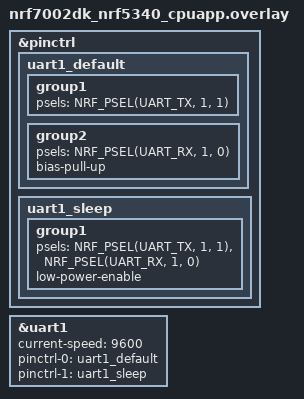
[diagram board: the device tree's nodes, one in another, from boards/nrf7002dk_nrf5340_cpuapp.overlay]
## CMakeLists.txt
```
#
# Copyright (c) 2022 Nordic Semiconductor ASA
#
# SPDX-License-Identifier: LicenseRef-Nordic-5-Clause
#

cmake_minimum_required(VERSION 3.20.0)

find_package(Zephyr REQUIRED HINTS $ENV{ZEPHYR_BASE})
project(GNSSProjekt3)

target_include_directories(app PUBLIC ${ZEPHYR_BASE}/subsys/net/ip)

target_sources(app
    PRIVATE
    src/main.c
    src/gps.c
    src/net_comm.c
    src/led_blink.c
)
```

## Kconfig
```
#
# Copyright (c) 2022 Nordic Semiconductor
#
# SPDX-License-Identifier: LicenseRef-Nordic-5-Clause
#

source "Kconfig.zephyr"

menu "Nordic Sta sample"

config CONNECTION_IDLE_TIMEOUT
	int "Time to be waited for a station to connect"
	default 30

config NRF70_QSPI_ENCRYPTION_KEY
	string "16 bytes QSPI encryption key, only for testing purposes"
	depends on BOARD_NRF7002DK_NRF5340_CPUAPP
	help
	  Specify the QSPI encryption key

config STA_CONN_TIMEOUT_SEC
	int "Overall Connection timeout i.e., time to be waited for a station to connect and get an IP address"
	# Zephyr DHCP retry is 1 minute, so set the default to 70 seconds
	default 70
	# 512 has no special meaning, just a reasonable upper limit
	range 0 512
	help
	  Specify the connection timeout, in seconds. This is the overall timeout i.e., time to be waited for
	  a station to connect and get an IP address. DHCP retries should be taken into account when setting
	  this value. If the timeout is set to 0, the connection will not timeout.

config STA_SAMPLE_START_WIFI_THREAD_STACK_SIZE
	int "Stack size for Wi-Fi start thread"
	default 4096
	help
	  Set the stack size for the Wi-Fi start thread.
	  
endmenu
```

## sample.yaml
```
sample:
  description: Wi-Fi station sample
    application
  name: Wi-Fi station
tests:
  sample.nrf7002.sta:
    sysbuild: true
    build_only: true
    integration_platforms:
      - nrf7002dk/nrf5340/cpuapp
    platform_allow: nrf7002dk/nrf5340/cpuapp
    tags: ci_build sysbuild ci_samples_wifi
  sample.nrf7002.sta.no_wifi_ready:
    sysbuild: true
    build_only: true
    extra_args: CONFIG_WIFI_READY_LIB=n
    integration_platforms:
      - nrf7002dk/nrf5340/cpuapp
    platform_allow: nrf7002dk/nrf5340/cpuapp
    tags: ci_build sysbuild ci_samples_wifi
  sample.nrf7001.sta:
    sysbuild: true
    build_only: true
    integration_platforms:
      - nrf7002dk/nrf5340/cpuapp/nrf7001
    platform_allow: nrf7002dk/nrf5340/cpuapp/nrf7001
    tags: ci_build sysbuild ci_samples_wifi
    skip: true
  sample.nrf7002_eks.sta:
    sysbuild: true
    build_only: true
    extra_args: SHIELD=nrf7002ek
    integration_platforms:
      - nrf5340dk/nrf5340/cpuapp
      - nrf52840dk/nrf52840
    platform_allow: nrf5340dk/nrf5340/cpuapp nrf52840dk/nrf52840
    extra_configs:
      - CONFIG_NET_TX_STACK_SIZE=3700
      - CONFIG_NET_RX_STACK_SIZE=3700
    tags: ci_build sysbuild ci_samples_wifi
  sample.nrf7001_eks.sta:
    sysbuild: true
    build_only: true
    extra_args: SHIELD=nrf7002ek_nrf7001
    integration_platforms:
      - nrf5340dk/nrf5340/cpuapp
      - nrf52840dk/nrf52840
    platform_allow: nrf5340dk/nrf5340/cpuapp nrf52840dk/nrf52840
    extra_configs:
      - CONFIG_NET_TX_STACK_SIZE=3700
      - CONFIG_NET_RX_STACK_SIZE=3700
    tags: ci_build sysbuild ci_samples_wifi
  sample.nrf7002_eb.thingy53.sta:
    sysbuild: true
    build_only: true
    extra_args: sta_SHIELD=nrf7002eb
    integration_platforms:
      - thingy53/nrf5340/cpuapp
    platform_allow: thingy53/nrf5340/cpuapp
    tags: ci_build sysbuild ci_samples_wifi
  sample.nrf7002eb_interposer_p1.nrf7002eb.sta:
    sysbuild: true
    build_only: true
    extra_args:
      - sta_SHIELD=nrf7002eb_interposer_p1 nrf7002eb
      - sta_SNIPPET=nrf70-wifi
    integration_platforms:
      - nrf54h20dk/nrf54h20/cpuapp
      - nrf54l15dk/nrf54l15/cpuapp
    platform_allow:
      - nrf54h20dk/nrf54h20/cpuapp
      - nrf54l15dk/nrf54l15/cpuapp
    tags: ci_build sysbuild ci_samples_wifi
```

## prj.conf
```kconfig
CONFIG_WIFI=y
CONFIG_WIFI_NRF70=y

#WPA supplicant
CONFIG_WIFI_NM_WPA_SUPPLICANT=y
CONFIG_WIFI_READY_LIB=y
CONFIG_NRF_WIFI_RPU_RECOVERY=y

CONFIG_WIFI_MGMT_EXT=y
CONFIG_WIFI_CREDENTIALS=y
CONFIG_WIFI_CREDENTIALS_STATIC=y
CONFIG_WIFI_CREDENTIALS_STATIC_SSID=""
CONFIG_WIFI_CREDENTIALS_STATIC_PASSWORD=""

#Networking
CONFIG_NETWORKING=y
CONFIG_NET_SOCKETS=y
CONFIG_NET_LOG=y
CONFIG_NET_IPV4=y
CONFIG_NET_UDP=y
CONFIG_NET_TCP=y
CONFIG_NET_DHCPV4=y

CONFIG_NET_PKT_RX_COUNT=8
CONFIG_NET_PKT_TX_COUNT=8


CONFIG_NET_BUF_RX_COUNT=128
CONFIG_NET_BUF_TX_COUNT=128
CONFIG_NRF70_RX_NUM_BUFS=16
CONFIG_HEAP_MEM_POOL_SIZE=120000
CONFIG_HEAP_MEM_POOL_IGNORE_MIN=y
CONFIG_NET_TC_TX_COUNT=1

CONFIG_NET_IF_UNICAST_IPV4_ADDR_COUNT=1
CONFIG_NET_MAX_CONTEXTS=5
CONFIG_NET_CONTEXT_SYNC_RECV=y

CONFIG_INIT_STACKS=y

CONFIG_NET_L2_ETHERNET=y

CONFIG_NET_CONFIG_SETTINGS=y 
CONFIG_NET_CONFIG_INIT_TIMEOUT=0

CONFIG_NET_SOCKETS_POLL_MAX=10

# Memories
CONFIG_MAIN_STACK_SIZE=5200
CONFIG_NET_TX_STACK_SIZE=4096
CONFIG_NET_RX_STACK_SIZE=4096
CONFIG_STA_SAMPLE_START_WIFI_THREAD_STACK_SIZE=5200

#Debugging
CONFIG_STACK_SENTINEL=y
CONFIG_DEBUG_COREDUMP=y
CONFIG_DEBUG_COREDUMP_BACKEND_LOGGING=y
CONFIG_DEBUG_COREDUMP_MEMORY_DUMP_MIN=y
CONFIG_SHELL_CMDS_RESIZE=n



CONFIG_ENTROPY_GENERATOR=y

CONFIG_NET_CONFIG_MY_IPV4_ADDR="192.168.1.99"
CONFIG_NET_CONFIG_MY_IPV4_NETMASK="255.255.255.0"
CONFIG_NET_CONFIG_MY_IPV4_GW="192.168.1.1"

CONFIG_NET_MGMT_EVENT_QUEUE_TIMEOUT=5000

#Logging
CONFIG_LOG=y
CONFIG_LOG_BUFFER_SIZE=2048
CONFIG_POSIX_CLOCK=y

#GTPA013 UART COMMUNICATION
CONFIG_SERIAL=y
CONFIG_UART_INTERRUPT_DRIVEN=n
CONFIG_UART_ASYNC_API=y


CONFIG_PRINTK=y

CONFIG_UART_ASYNC_API=y
CONFIG_UART_INTERRUPT_DRIVEN=n

CONFIG_HEAP_MEM_POOL_SIZE=120000


#Traccar HTTP section
CONFIG_HTTP_CLIENT=y
#needed to activate float
CONFIG_CBPRINTF_FP_SUPPORT=y

#needed for leds
CONFIG_GPIO=y
```

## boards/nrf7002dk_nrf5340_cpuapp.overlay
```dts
// Allow uart1 to be used as a normal UART instead of forwarding to network core for serial logging
/delete-node/ &gpio_fwd;



&pinctrl {

    uart1_default: uart1_default {
		group1 {
			psels = <NRF_PSEL(UART_TX, 1, 1)>;
		};
		group2 {
			psels = <NRF_PSEL(UART_RX, 1, 0)>;
			bias-pull-up;
		};
	};

	uart1_sleep: uart1_sleep {
		group1 {
			psels = <NRF_PSEL(UART_TX, 1, 1)>,
				<NRF_PSEL(UART_RX, 1, 0)>;
			low-power-enable;
		};
	};

};





&uart1 {
	status = "okay";
	current-speed = <9600>;
	pinctrl-0 = <&uart1_default>;
	pinctrl-1 = <&uart1_sleep>;
	pinctrl-names = "default", "sleep";
	
};
```

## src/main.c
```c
#include <stdio.h> //standard c lib
#include <stdlib.h> //standard c lib
#include <zephyr/kernel.h>
#include <zephyr/drivers/uart.h> //uart functions and macros

#include <zephyr/sys/util.h> //utility macros(SYS_FOREVER_US)


#include <zephyr/net/net_if.h> //network interfaces 
#include <zephyr/net/net_mgmt.h> //api for controlling net events
#include <zephyr/net/net_event.h> //defines net events
#include <zephyr/net/wifi_mgmt.h> //wifi management scan, connect
 
#include <net/wifi_mgmt_ext.h> //needed for wifi credentials //rxtended API for working with WIFI credentials
#include <net/wifi_ready.h> // macros for wifi interface readyness checking

//SOCKET headers
#include <zephyr/net/socket.h>
#include <zephyr/net/http/client.h>

//led file header
#include "led_blink.h"
#include "gps.h"
#include "net_comm.h"

//logging system setup
LOG_MODULE_REGISTER(main, LOG_LEVEL_INF); //main - module name, LoG_LEVEL_INF - info and above 


int main(void)
{

    printk("main started\n");
    printk("beginning\n");

    if(init_led() != 0){
        return 0;
    }
    blink_led(1, 2000);
    
    struct net_if *iface = net_if_get_default(); //get primary network interface
    if (iface == NULL) {
        LOG_ERR("Wi-Fi interface not found!");
        return 0;
    }

    if(wifi_init(iface) != 0) return 0;

        
    connect_to_wifi_with_backup(iface);
    

	k_sleep(K_MSEC(5000)); // DELAY JER SE INACE PRECOMPLETE I WIFI SETUP COMPLETE ISPISU  NAKON UART TEXTOVA ZBOG NEKOG RAZLOGA
    
    printk("Starting GNSS listener...\n");
	//check if uart device is ready
    if (!device_is_ready(uart)) {
        printk("UART device not ready!\n");
        return 0;
    }
    
    k_sleep(K_MSEC(2000)); // Give GPS time to boot
    configure_gtpa013("$PMTK314,0,1,0,1,0,0,0,0,0,0,0,0,0,0,0,0,0,0,0*28\r\n"); // set only RMC nmea sentence and GGA
    k_sleep(K_MSEC(2));

    //configure_gtpa013("$PMTK220,1000*1F\r\n");// se output interval
    //k_sleep(K_MSEC(10000));

    if(uart_init() != 0) return 0;

    printk("UART RX interrupt listener started\n");

    k_sleep(K_MSEC(5000));
        
    while (1) {
        k_sem_take(&gps_data_sem, K_FOREVER);

        // parse + send latest
        if (nmea_parser(latest_nmea_sentence)) {
            send_to_traccar(lat_dec, lon_dec, user_speed, altitude);
        }

        //if connected is set to false(in case a dicsonnect happened), attempt to reconnect
        if(!connected){
            printk("Attemping to recconnect wifi.");
            connect_to_wifi_with_backup(iface);
        }
        


        k_msleep(1);
    }
        
        
    
}
```

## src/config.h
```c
#ifndef CONFIG_H
#define CONFIG_H

#define SERVER_IP   ""
#define SERVER_PORT 5055
#define DEVICE_ID   ""

#endif 
```

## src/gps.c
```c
#include "gps.h"

#include <stdio.h> 
#include <stdlib.h> 
#include <zephyr/kernel.h>
#include <zephyr/drivers/uart.h> //uart functions and macros
#include <zephyr/sys/util.h> //utility macros(SYS_FOREVER_US)

#define UART_BUF_COUNT 2

#define UART_BUF_SIZE 83   // 82 max length of one nmea sentence

static uint8_t *uart_buffers[UART_BUF_COUNT];
static int uart_buf_idx = 0;
#define UART_DEVICE_NODE DT_NODELABEL(uart1)   //defines macro for UART device node, specifically uart1
const struct device *uart = DEVICE_DT_GET(UART_DEVICE_NODE); //fetch UART device using macro, stores in pointer uart used to comunicate with UART hardware

#define GTPA_DATA_BUFFER_SIZE 1024
static uint8_t gtpa_data_buffer[GTPA_DATA_BUFFER_SIZE];
static size_t gtpa_data_buffer_pos = 0;
char latest_nmea_sentence[128];
K_SEM_DEFINE(gps_data_sem, 0, 1);  //binary semaphore

//amount of commas in a NMEA sentence 
#define NMEA_COMMA_AMOUNT 16

//global data containers for latitude and longitude values
double lat_dec = 0;
double lon_dec = 0;
double user_speed = 0;
double altitude = 0;


static bool validate_checksum(const char *nmea){
    //fint the * marking the beggining of checksum portion
    const char *checksum_str = strchr(nmea, '*');
    if(!checksum_str){
        printk("Invalid checksum\n");
        return false;
    }
    //put the two characters after * representing checksum and a terminator into a buffer
    char checksum_buf[3] = {checksum_str[1], checksum_str[2], '\0'};
    
    //convert checksum characters into base 16
    uint8_t converted_checksum = (uint8_t)strtol(checksum_buf, NULL, 16);

    //calculate checksum - XOR of all characters between $ and *
    uint8_t calculated_checksum = 0;
    for(const char *p = nmea + 1; p < checksum_str; ++p){
        calculated_checksum ^= (uint8_t)(*p);
    }
    printk("Calculated checksum: %02X\n", calculated_checksum);

    //compare checksums, if they match sentence is not corrupted
    if(calculated_checksum != converted_checksum){
        printk("Checksum mismatch: expected %02X, got %02X\n", converted_checksum, calculated_checksum);
        return false;
    }
    return true;
}

float nmea_to_decimal(const char *coord, const char *dir, bool is_latitude){
    float deg = 0;
    float min = 0;
    
    //latitude ddmm.mmmm longitude dddmm.mmmm
    //spliting d and m sections into deg and min floats
    if(is_latitude){
        //2 digits for deg
        char deg_str[3] = {0};
        strncpy(deg_str, coord, 2);
        deg = atof(deg_str);
        min = atof(coord + 2);
    }else{
        //3 digits for deg
        char deg_str[4] = {0};
        strncpy(deg_str, coord, 3);
        deg = atof(deg_str);
        min = atof(coord + 3);
    }
    //formula for converting into decimal
    float decimal = deg + (min / 60);
    // fot lat N is positive, S is negative
    // for lon E is positive, S is negative
    if(dir[0] == 'S' || dir[0] == 'W'){
        decimal = -decimal;
    }

    return decimal;
}

//function to parse nmea sentences
bool nmea_parser(const char *nmea){
    //if sum doesnt match checksum value sentence is corrupted
    if(!validate_checksum(nmea)){
        printk("Invalid checksum. Skipping\n");
        return false;
    }

    char par_buf[128];
    //copy data into modifiable buffer
    strncpy(par_buf, nmea, sizeof(par_buf) - 1);
    par_buf[sizeof(par_buf) - 1] = '\0';

    //separate data by commas
    char *nmea_sections[16];
    int i = 0; // also the amount of commas
    //strtok - function do split string by certain character(in this case ,)
    char *nmea_section = strtok(par_buf, ",");
    while(nmea_section != NULL && i < 16){
        nmea_sections[i++] = nmea_section;
        nmea_section = strtok(NULL, ",");
    }

    if(strncmp(nmea, "$GPRMC", 6) == 0){
    
        const char *utc_time = nmea_sections[1];
        const char *status = nmea_sections[2];
        const char *latitude_raw = nmea_sections[3];
        const char *latitude_dir = nmea_sections[4];
        const char *longitude_raw = nmea_sections[5];
        const char *longitude_dir = nmea_sections[6];
        const char *speed = nmea_sections[7];
        const char *course = nmea_sections[8];
        const char *date = nmea_sections[9];

        if(status[0] != 'A'){
            printk("  GPRMC status not valid: %s\n", status[0] == 'A' ? "Active" : "Void");
            return false;
        }
        // converting lat and lon from ddmm.mmmm to proper decimals
        lat_dec = nmea_to_decimal(latitude_raw, latitude_dir, true);
        lon_dec = nmea_to_decimal(longitude_raw, longitude_dir, false);
        user_speed = atof(speed);
        // Print parsed data
        printk("GPRMC Parsed:\n");
        printk("  UTC Time: %s\n", utc_time);
        printk("  Status: %s\n", status[0] == 'A' ? "Active" : "Void");
        printk("  Latitude: %0.6f\n", lat_dec);
        printk("  Longitude: %0.6f\n", lon_dec);
        printk("  Speed (knots): %s\n", speed);
        printk("  Course: %s\n", course);
        printk("  Date: %s\n", date);
        return true;

    }else if(strncmp(nmea, "$GPGGA", 6) == 0){
        //const char *utc_time = nmea_sections[1];
        const char *latitude_raw = nmea_sections[2];
        const char *latitude_dir = nmea_sections[3];
        const char *longitude_raw = nmea_sections[4];
        const char *longitude_dir = nmea_sections[5];
        const char *fix_quality = nmea_sections[6];
        const char *altitude_raw = nmea_sections[9];

        if(fix_quality[0] != '1' && fix_quality[0] != '2'){
            printk("No GPS fix\n");
            return false;
        }

        lat_dec = nmea_to_decimal(latitude_raw, latitude_dir, true);
        lon_dec = nmea_to_decimal(longitude_raw, longitude_dir, false);
        altitude = atof(altitude_raw); // turn alt into float
        
        printk("GPGGA Parsed:\n");
        printk("  Latitude: %0.6f\n", lat_dec);
        printk("  Longitude: %0.6f\n", lon_dec);
        printk("  Altitude: %0.3f m\n", altitude);
        printk("  Fix Quality: %s\n", fix_quality);
        return true;
    }
        
    return false;
    
}




static void uart_cb(const struct device *dev, struct uart_event *evt, void *user_data)
{
    int err;

	//switch picking what to do based on the event type
    switch (evt->type) {
		//when data is ready to be read
    case UART_RX_RDY:

        //better saving of data which checks for end of sentence and resets buffer position on end
        for(size_t i = 0; i < evt->data.rx.len; i++){
            if(gtpa_data_buffer_pos < GTPA_DATA_BUFFER_SIZE - 1){
                gtpa_data_buffer[gtpa_data_buffer_pos++] = evt->data.rx.buf[evt->data.rx.offset + i];

                if(evt->data.rx.buf[evt->data.rx.offset + i] == '\n'){
                    //end of sentence detected, terminate it and print out data and reset buffer
                    gtpa_data_buffer[gtpa_data_buffer_pos] = '\0';
                    
                    
                   
                    memcpy(latest_nmea_sentence, gtpa_data_buffer, gtpa_data_buffer_pos); 
                     
                    printk("[%u]Full NMEA sentence: %s", k_uptime_get_32(), gtpa_data_buffer);

                    //nmea_parser((const char *)gtpa_data_buffer);
                    k_sem_give(&gps_data_sem);

                    gtpa_data_buffer_pos = 0;
                }
            }else{
                printk("App buffer overflow\n");
                gtpa_data_buffer_pos = 0;
            }
        }
        break;
		//when uart driver requests a buffer for recieving data
    case UART_RX_BUF_REQUEST:
        //switch from currently active to the other buffer
        uart_buf_idx = (uart_buf_idx + 1) % UART_BUF_COUNT;
        uint8_t *next_buf = uart_buffers[uart_buf_idx];

        err = uart_rx_buf_rsp(uart, next_buf, UART_BUF_SIZE);
        if (err) {
            printk("uart_rx_buf_rsp error: %d\n", err);
        }
        break;
     
    case UART_RX_DISABLED:
        printk("UART RX Disabled, re-enabling...\n");
        
        err = uart_rx_enable(uart, uart_buffers[0], UART_BUF_SIZE, SYS_FOREVER_US);
        if (err) {
            printk("uart_rx_enable error: %d\n", err);
        }

        break;
    default:
        break;
    }
}

//function for sending commands to gps module
void configure_gtpa013(const char* command){

    size_t len = strlen(command);
    int ret = uart_tx(uart, command, len, SYS_FOREVER_US);
    k_sleep(K_MSEC(1000));
    if (ret) {
        printk("Failed to send GPS command (err %d)\n", ret);
    } else {
        printk("Sent GPS command: %s\n", command);
    }
}

int uart_init(void)
{
    int err;

    int ret = uart_callback_set(uart, uart_cb, NULL);
    if (ret) {
        printk("Failed to set UART callback: %d\n", ret);
        return -1;
    }

    //allocate both buffers
    for (int i = 0; i < UART_BUF_COUNT; i++) {
        uart_buffers[i] = k_malloc(UART_BUF_SIZE);
        if (!uart_buffers[i]) {
            printk("Failed to allocate UART buffer %d\n", i);
            return -1;
        }
    }
    k_msleep(1000);
    //enable uart rx with the first buffer
    err = uart_rx_enable(uart, uart_buffers[0], UART_BUF_SIZE, SYS_FOREVER_US);
    if (err) {
        printk("uart_rx_enable failed: %d\n", err);
    }
    return 0;
}
```

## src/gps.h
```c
// gps.h
#ifndef GPS_H
#define GPS_H

#include <stdio.h> 
#include <stdlib.h> 
#include <zephyr/kernel.h>
#include <zephyr/drivers/uart.h> //uart functions and macros
#include <zephyr/sys/util.h> //utility macros(SYS_FOREVER_US)

#define UART_BUF_COUNT 2
#define UART_BUF_SIZE 83  // 82 max length of one NMEA sentence
#define GTPA_DATA_BUFFER_SIZE 1024

extern const struct device *uart;

extern double lat_dec;
extern double lon_dec;
extern double altitude;
extern double user_speed;

extern char latest_nmea_sentence[128];

extern struct k_sem gps_data_sem;

int uart_init(void);
bool nmea_parser(const char *nmea);
void configure_gtpa013(const char *command);
float nmea_to_decimal(const char *coord, const char *dir, bool is_latitude);

#endif
```

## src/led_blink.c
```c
#include "led_blink.h"
#include <zephyr/kernel.h>
//gpio/led header
#include <zephyr/drivers/gpio.h>
//1 long - after led init
//2 blinks -location sent
//1 long - connected to wifi
//5 short - failed to connect/disconnected

//defines LED0_NODE from the led0 alias 
#define LED0_NODE DT_ALIAS(led0)

//grab gpio config for led0, gpio_dt_spec contains structures to control the led
static const struct gpio_dt_spec led0 = GPIO_DT_SPEC_GET(LED0_NODE, gpios);

//function controlling led blinking
void blink_led(int times, int blink_delay){
    for (int i = 0; i < times; i++)
    {
        gpio_pin_set_dt(&led0, 1); //set led to on
        k_msleep(blink_delay);
        gpio_pin_set_dt(&led0, 0); //set led to off
        k_msleep(blink_delay);
    }
    
}

int init_led(void){
    //led ready check
    if(!gpio_is_ready_dt(&led0)){
        printk("Led is not ready. Stopping...");
        return -1;
    }
    //start led OFF
    int ret = gpio_pin_configure_dt(&led0, GPIO_OUTPUT_INACTIVE);
    if(ret < 0){
        printk("Failed to intially config led");
        return -1;
    }
    return 0;
}
```

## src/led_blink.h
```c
#ifndef LED_BLINK_H
#define LED_BLINK_H
#include <zephyr/kernel.h>
#include <zephyr/drivers/gpio.h>

void blink_led(int times, int blink_delay);
int init_led(void);

#endif
```

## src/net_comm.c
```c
#include "net_comm.h"
#include <stdio.h> //standard c lib
#include <stdlib.h> //standard c lib
#include <zephyr/kernel.h>

#include <zephyr/sys/util.h> //utility macros(SYS_FOREVER_US)


#include <zephyr/net/net_if.h> //network interfaces 
#include <zephyr/net/net_mgmt.h> //api for controlling net events
#include <zephyr/net/net_event.h> //defines net events
#include <zephyr/net/wifi_mgmt.h> //wifi management scan, connect
 
#include <net/wifi_mgmt_ext.h> //needed for wifi credentials //rxtended API for working with WIFI credentials
#include <net/wifi_ready.h> // macros for wifi interface readyness checking

//SOCKET headers
#include <zephyr/net/socket.h>
#include <zephyr/net/http/client.h>
#include <zephyr/data/json.h>


//led file header
#include "led_blink.h"
//server params
#include "config.h"

//wifi ready support
static K_SEM_DEFINE(wifi_ready_sem, 0, 1);
static bool wifi_ready_status = false;

//combining 4 event types to call in a callback
#define WIFI_EVENTS (NET_EVENT_WIFI_CONNECT_RESULT | NET_EVENT_WIFI_DISCONNECT_RESULT | NET_EVENT_WIFI_SCAN_RESULT | NET_EVENT_WIFI_SCAN_DONE)
static struct net_mgmt_event_callback wifi_cb; //event listener for wifi connection
bool connected = false; 

//suport for scanning for wifi networks
K_SEM_DEFINE(scan_sem, 0, 1); // semaphor for scanning
#define SCAN_TIMEOUT 10000
#define MAX_OPEN_RESULTS 10
static struct wifi_scan_result open_results[MAX_OPEN_RESULTS]; //container for info of networks found during wifi scanning
static int open_result_count = 0;
static bool open_network_available = false; //flag to check if an open network i available 


K_SEM_DEFINE(gps_data_ready, 0, 1);




//zephyr is event driven, it connects to wifi in the background
//later it shows the result through a callback


//logging system setup
LOG_MODULE_REGISTER(net_comm, LOG_LEVEL_INF); //main - module name, LoG_LEVEL_INF - info and above


//saving scanned networks into open results
static void scan_result_handler(struct net_mgmt_event_callback *cb){
    const struct wifi_scan_result *entry = (const struct wifi_scan_result *)cb->info;
	//char mac_buf[sizeof("xx:xx:xx:xx:xx:xx")];


    if(entry->security == WIFI_SECURITY_TYPE_NONE){
        if(open_result_count < MAX_OPEN_RESULTS){
            open_results[open_result_count] = *entry;
            open_result_count++;
            open_network_available = true;
            if (open_result_count == 1) {
		        printk("Num | SSID                             | RSSI | Channel | BSSID\n");
	        }

            printk("%-3d | %-32s | %-4d | %-7d\n",
		        open_result_count,
		        entry->ssid,
		        entry->rssi,
		        entry->channel);

        }else{
            printk("Open result list full, Skipping: %s\n", entry->ssid);
        }
    }
}


//function for scanning for open networks
static int scan_for_open_networks(struct net_if *iface){
    
    //reset amount of found networks
    open_result_count = 0;
    struct wifi_scan_params params = { 0 };

    //actuall scanning
    if(net_mgmt(NET_REQUEST_WIFI_SCAN, iface, &params, sizeof(params)) != 0){
        LOG_ERR("Wi-Fi scan request failed");
        return -1;
    }

    k_sem_take(&scan_sem, K_MSEC(SCAN_TIMEOUT));
    return 0;

}

static int connect_to_open_wifi(struct net_if *iface){
    //if flag is set to false no open network if found
    if(!open_network_available){
        LOG_WRN("No open networks found");
        return -ENOENT;
    }

    for (size_t i = 0; i < open_result_count; i++){
    
        //parameters for an open network
        struct wifi_connect_req_params params = {
            .ssid = open_results[i].ssid,
            .ssid_length = strlen(open_results[i].ssid),
            .security = WIFI_SECURITY_TYPE_NONE,
            .channel = WIFI_CHANNEL_ANY,
            .timeout = SYS_FOREVER_MS,
        };

        LOG_INF("Connecting to open network: %s", open_results[i].ssid);
        //connecting
        net_mgmt(NET_REQUEST_WIFI_CONNECT, iface, &params, sizeof(params));
        //wait up to 10 seconds for connection to be confirmed
        int tries = 0;
        //loop waiting untill wifi connects or times out
        while (!connected && tries++ < 10) {
            printk("Trying to connect to network %d: %d", i, tries);
            k_sleep(K_SECONDS(1));
        }

        if(connected){ 
            LOG_INF("Connected to: %s", open_results[i].ssid);
            break;
        }
    }
    
    open_network_available = false; // setting flag back to false for the next time

    return 0;
}
//connecting to wifi network in with defined params
static void connect_to_known_wifi(struct net_if *iface){
    
	net_mgmt(NET_REQUEST_WIFI_CONNECT_STORED, iface, NULL, 0); 
    
    
    LOG_INF("Waiting for Wi-Fi connection result...");
    // Wait up to 10 seconds for connection to be confirmed
    int tries = 0;
    //loop waiting untill wifi connects or times out
    while (!connected && tries++ < 10) {
        printk("Trying to connect to known network: %d", tries);
        k_sleep(K_SECONDS(1));
    }

    if (!connected) {
        blink_led(5, 100);
        LOG_WRN("Connection to known Wi-Fi failed or timed out");
    } else {
        LOG_INF("Connected to known Wi-Fi successfully");
    }
}

void connect_to_wifi_with_backup(struct net_if *iface){
    connect_to_known_wifi(iface);

    //if device manages to connect to known wifi no need to continue
    if(connected){
        return;
    }
    

    LOG_INF("Falling back to open networks == 0");
    /* SCANNING OVERALL
    WORKS USING A net_mgmt  in scan_for_open_networks meaning in need to a callback like the the wifi event handler,
    2 events this uses are scanning result and scanning done,
    scanning done calls the scan_done_handler which checks the status of the scan,
    scanning result calls scan_result_handler which  which is used to check for open networks
    in all the found networks and stores the for use when connecting_to them,
    after all that if any opens network are found connect_to_open_wifi goes ahead and connects to one similar to how connecting to known works*/
    //if scanning successfully finds any networks continue to connecting to open network
    if(scan_for_open_networks(iface) == 0){
        connect_to_open_wifi(iface);
    }
}

//callback for wifi ready
void wifi_ready_cb(bool ready){
    LOG_INF("Wi-Fi ready state changed: %s", ready ? "READY" : "NOT READY");
    wifi_ready_status = ready;
    k_sem_give(&wifi_ready_sem);
}


//function runs when when wifi connect event happens
void wifi_event_handler(struct net_mgmt_event_callback *cb, uint32_t mgmt_event, struct net_if *iface/*, void *info*/){
    LOG_INF("Mgmt event: 0x%x", mgmt_event);

    
    //cb - pointer to callback, contains event info
    //mgmt_event - event code
    //iface - network interface

    //takes info from cb and casts into wifi_status struct
    //wifi_status  zephyr struct for reporting wifi event results
    //const struct wifi_status *status = cb->info; //OLD

    switch (mgmt_event)
    {
    case NET_EVENT_WIFI_CONNECT_RESULT://if wifi connection result happened(succes or fail)
        //const struct wifi_status *status = info; //event handler includes info parameter directly
		const struct wifi_status *status =(const struct wifi_status *) cb->info;
        if(status->status == 0 && net_if_is_up(iface)){ //if success (status = 0 ->success)
            //set connected flag to true and log - LOG_DEFAULT_LEVEL must be 3
            connected = true;
            LOG_INF("Connected to wifi and interface is up.");
            blink_led(1, 800);
        } else{
            LOG_ERR("Failed to connect (%d), connect event fired off but interface is off", status->status);
            blink_led(5, 100);
        }
        break;
    case NET_EVENT_WIFI_DISCONNECT_RESULT://if disconnection is detected set connect to false
        connected = false;
        LOG_WRN("Wifi disconnected.");
        blink_led(5, 100);
        break;
    case NET_EVENT_WIFI_SCAN_RESULT:
        scan_result_handler(cb);
        break;
    case NET_EVENT_WIFI_SCAN_DONE:
        //tells about successfullnes of wifi scanning
        //gets status from callback
        const struct wifi_status *status_scan = (const struct wifi_status *)cb->info;
        if(status_scan->status == 0){
            printk("Scan completed successfully\n");
        } else{
            printk("Scan failed with status %d\n", status_scan->status);
        }
        //open_result_count = 0;
        //semaphore to synchronise with scan for open networks
        k_sem_give(&scan_sem);
        break;
    
    default:
        break;
    }
    
}




//function which formats a request, opens a socket and send the request to a server
void send_to_traccar(double lat, double lon, double speed, double alt){
    //int speed = 10;
    
    // declares structure to hold srever's IP and PORT in IPv4
    struct sockaddr_in server_addr;
    int sock;
    //buffer to hold the htttp GET request string
    char request[512];
    
    //formats a HTTP GET string contaiining id, lat, lon, speed and alt
    snprintf(request, sizeof(request),
         "GET /?id=%s&lat=%0.6f&lon=%0.6f&speed=%0.02f&altitude=%0.02f HTTP/1.0\r\n\r\n",
         DEVICE_ID, lat, lon, speed, alt);
    
    //creates a new TCP socket AF_INTE:IPv4, SOCK_STREAM:TCP, IPPROTO_TCP-  specifies TCP protocol
    sock = socket(AF_INET, SOCK_STREAM, IPPROTO_TCP);
    if (sock < 0) {
        printf("Failed to create socket\n");
        return;
    }

    //set server address
    server_addr.sin_family = AF_INET; 
    server_addr.sin_port = htons(SERVER_PORT); //convertscto network byte order and stores it
    server_addr.sin_addr.s_addr = inet_addr(SERVER_IP); //converts IP into a 32 bit binary in network byte order

    //attempts to connect socket to Traccar server at specified IP and PORT
    if (connect(sock, (struct sockaddr *)&server_addr, sizeof(server_addr)) < 0) {
        printf("Failed to connect to server\n");
        close(sock);
        return;
    }
    //prints full http request for DEBUGGING
    printf("Final request: %s\n", request);

    //sends HTTP request string over the established TCP socked
    if(send(sock, request, strlen(request), 0) < 0){
        printf("Failed to send location\n");
    }else {
        printf("Location sent successfully\n");
        blink_led(2, 200);
    }
    
    //close socket
    close(sock);
}


int wifi_init(struct net_if *iface){

    //wifi callback registration, tells zephyr to listen for a wifi connection event and call wifi event handler when it happens
    net_mgmt_init_event_callback(&wifi_cb, wifi_event_handler, WIFI_EVENTS);
    net_mgmt_add_event_callback(&wifi_cb);

    //registering wifi ready callback
    wifi_ready_callback_t cb;
    cb.wifi_ready_cb = wifi_ready_cb;
    int ret = register_wifi_ready_callback(cb, iface);
    if(ret != 0){
        LOG_ERR("Failed to register wifi ready cb: %d", ret);
        return -1;
    }
    //waiting for wifi to be ready
    LOG_INF("Waiting for Wi-Fi to become ready");
    k_sem_take(&wifi_ready_sem, K_FOREVER);
    if(!wifi_ready_status){
        LOG_ERR("Wi-Fi is not ready. Continuing"); 
    }
    return 0;
}
```

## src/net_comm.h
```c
#ifndef NET_COMM_H
#define NET_COMM_H

#include "net_comm.h"
#include <stdio.h> //standard c lib
#include <stdlib.h> //standard c lib
#include <zephyr/kernel.h>

#include <zephyr/sys/util.h> //utility macros(SYS_FOREVER_US)


#include <zephyr/net/net_if.h> //network interfaces 
#include <zephyr/net/net_mgmt.h> //api for controlling net events
#include <zephyr/net/net_event.h> //defines net events
#include <zephyr/net/wifi_mgmt.h> //wifi management scan, connect
 
#include <net/wifi_mgmt_ext.h> //needed for wifi credentials //rxtended API for working with WIFI credentials
#include <net/wifi_ready.h> // macros for wifi interface readyness checking

//SOCKET headers
#include <zephyr/net/socket.h>
#include <zephyr/net/http/client.h>
#include <zephyr/data/json.h>


//led file header
#include "led_blink.h"
//server config
#include "config.h"

extern bool connected;

void wifi_ready_cb(bool ready);
void wifi_event_handler(struct net_mgmt_event_callback *cb, uint32_t mgmt_event, struct net_if *iface);
void connect_to_wifi_with_backup(struct net_if *iface);
void send_to_traccar(double lat, double lon, double speed, double alt);
int wifi_init(struct net_if *iface);


#endif
```
